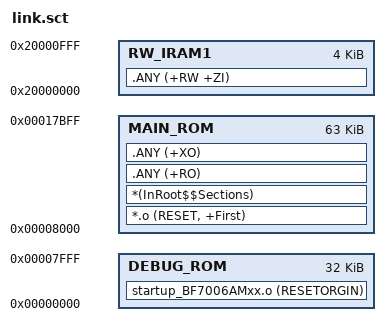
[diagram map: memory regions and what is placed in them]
; *************************************************************
; *** Scatter-Loading Description File generated by uVision ***
; *************************************************************

LR_IROM2 0x00000000 0x00008000 {    ; load region size_region
  DEBUG_ROM 0x00000000 0x00008000  {  ; load address = execution address
   startup_BF7006AMxx.o (RESETORGIN)
  }
}

LR_IROM1 0x00008000 0x0000FC00  {    ; load region size_region
  MAIN_ROM 0x00008000 0x0000FC00  {  ; load address = execution address
   *.o (RESET, +First)
   *(InRoot$$Sections)
   .ANY (+RO)
   .ANY (+XO)
  }
  RW_IRAM1 0x20000000 0x00001000  {  ; RW data
   .ANY (+RW +ZI)
  }
}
